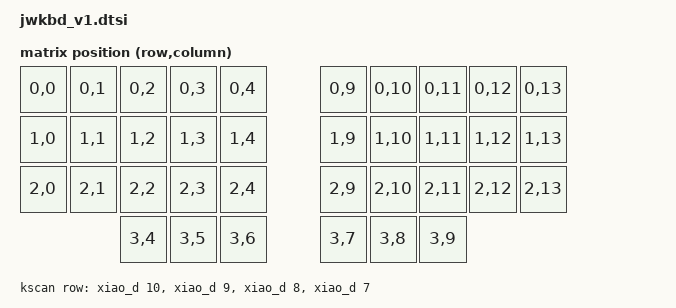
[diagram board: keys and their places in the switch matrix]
// This file was generated from a template. Edit it to match your keyboard.
// See https://zmk.dev/docs/development/hardware-integration/new-shield for more
// instructions.

#include <dt-bindings/zmk/matrix_transform.h>
#include <physical_layouts.dtsi>

#include "jwkbd_v1-layouts.dtsi"
/ {
    chosen {
        zmk,physical-layout = &physical_layout0;
    };

    kscan: kscan {
        compatible = "zmk,kscan-gpio-matrix";
        diode-direction = "col2row";
        wakeup-source;

        // Replace these comments with the GPIO pins in the matrix.
        // See https://zmk.dev/docs/development/hardware-integration/new-shield#shield-overlays
        row-gpios
            = <&xiao_d 10 (GPIO_ACTIVE_HIGH | GPIO_PULL_DOWN)>
            , <&xiao_d 9 (GPIO_ACTIVE_HIGH | GPIO_PULL_DOWN)>
            , <&xiao_d 8 (GPIO_ACTIVE_HIGH | GPIO_PULL_DOWN)>
            , <&xiao_d 7 (GPIO_ACTIVE_HIGH | GPIO_PULL_DOWN)>
            ;
    };

    default_transform: default_transform {
        compatible = "zmk,matrix-transform";
        columns = <14>;
        rows = <4>;

        map = <
            RC(0, 0) RC(0, 1) RC(0, 2) RC(0, 3) RC(0, 4)                                           RC(0, 9) RC(0, 10) RC(0, 11) RC(0, 12) RC(0, 13)
            RC(1, 0) RC(1, 1) RC(1, 2) RC(1, 3) RC(1, 4)                                           RC(1, 9) RC(1, 10) RC(1, 11) RC(1, 12) RC(1, 13)
            RC(2, 0) RC(2, 1) RC(2, 2) RC(2, 3) RC(2, 4)                                           RC(2, 9) RC(2, 10) RC(2, 11) RC(2, 12) RC(2, 13)
                                                RC(3, 4) RC(3, 5) RC(3, 6)      RC(3, 7) RC(3, 8)  RC(3, 9)
        >;
    };

    physical_layout0: physical_layout_0 {
        compatible = "zmk,physical-layout";
        display-name = "Default Layout";
        kscan = <&kscan>;
        transform = <&default_transform>;
    };
};
